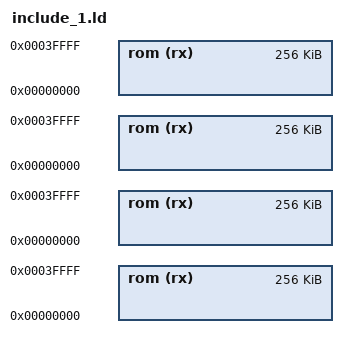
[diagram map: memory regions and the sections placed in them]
INCLUDE  hello
INCLUDE  hello2

MEMORY {
rom (rx)  : ORIGIN = 0, LENGTH = 256K
rom (rx)  : ORIGIN = 0, LENGTH = 256K
rom (rx)  : ORIGIN = 0 LENGTH = 256K
rom (rx)  : ORIGIN = 0, LENGTH = 256K
 }  

MEMORY { }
